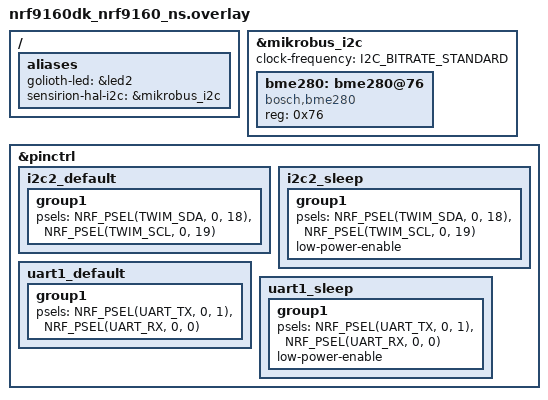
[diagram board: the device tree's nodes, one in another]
/*
 * Copyright (c) 2023 Golioth, Inc.
 *
 * SPDX-License-Identifier: Apache-2.0
 */

/ {
	aliases {
		golioth-led = &led2;
		sensirion-hal-i2c = &mikrobus_i2c;
	};
};

&mikrobus_i2c {
	status = "okay";

	/* SPS30 max clock frequency is 100 kbit/s */
	clock-frequency = <I2C_BITRATE_STANDARD>;

	bme280: bme280@76 {
		compatible = "bosch,bme280";
		reg = <0x76>;
	};
};

&pinctrl {
	/*
	 * The original Arduino Uno provides the same SCL/SDA on two sets of
	 * pins, but the nRF9160 DK maps these pins to two different pairs of
	 * GPIO. When using the Arduino Uno Click Shield board with the nRF9160
	 * DK, the P0.18/P0.19 pair must be used.
	 */
	i2c2_default: i2c2_default {
		group1 {
			psels = <NRF_PSEL(TWIM_SDA, 0, 18)>,
				<NRF_PSEL(TWIM_SCL, 0, 19)>;
		};
	};

	i2c2_sleep: i2c2_sleep {
		group1 {
			psels = <NRF_PSEL(TWIM_SDA, 0, 18)>,
				<NRF_PSEL(TWIM_SCL, 0, 19)>;
			low-power-enable;
		};
	};

	/*
	 * The default pin group for the nRF9160 DK includes RTS/CTS HW flow
	 * control, but the Arduino Uno Click Shield board does not connect
	 * these pins (only TX/RX are connected on the shield). This keeps RX/TX
	 * on the same pins, but just removes RTS/CTS from the pin groups.
	 */
	uart1_default: uart1_default {
		group1 {
			psels = <NRF_PSEL(UART_TX, 0, 1)>,
				<NRF_PSEL(UART_RX, 0, 0)>;
		};
	};

	uart1_sleep: uart1_sleep {
		group1 {
			psels = <NRF_PSEL(UART_TX, 0, 1)>,
				<NRF_PSEL(UART_RX, 0, 0)>;
			low-power-enable;
		};
	};
};
